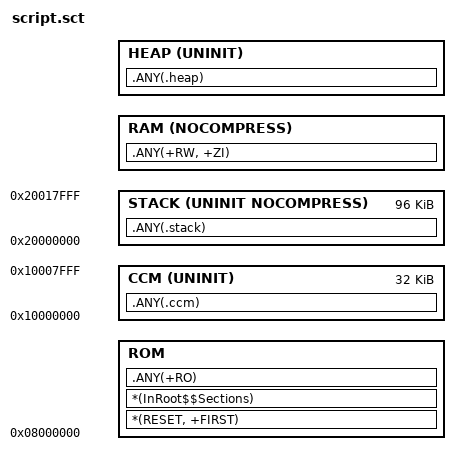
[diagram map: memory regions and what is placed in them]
/*******************************************************************************
@file     stm32l4xx.sct
@author   Rajmund Szymanski
@date     11.12.2019
@brief    Scatter file for STM32L476VG device with 1024KB FLASH and 128KB RAM
*******************************************************************************/

FLASH 0x08000000 0x00100000
{
	ROM +0
	{
		*(RESET, +FIRST)
		*(InRoot$$Sections)
		.ANY(+RO)
	}

	CCM 0x10000000 UNINIT 0x00008000
	{
		.ANY(.ccm)
	}

	STACK 0x20000000 UNINIT NOCOMPRESS 0x00018000
	{
		.ANY(.stack)
	}

	RAM ALIGNEXPR(+0, 8) NOCOMPRESS
	{
		.ANY(+RW, +ZI)
	}

	HEAP ALIGNEXPR(+0, 8) UNINIT
	{
		.ANY(.heap)
	}
}
